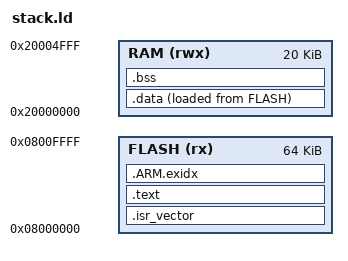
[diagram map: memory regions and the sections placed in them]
/* SPDX-License-Identifier: Apache-2.0 */
/* Copyright 2026 Junior Deogracias */
/* STM32F103C8 as common/stm32f103c8.ld, with a 2 KiB stack (__stack_limit) */
MEMORY
{
    FLASH (rx) : ORIGIN = 0x08000000, LENGTH = 64K
    RAM (rwx)  : ORIGIN = 0x20000000, LENGTH = 20K
}
ENTRY(Reset_Handler)
_estack = ORIGIN(RAM) + LENGTH(RAM);
__stack_limit = _estack - 2048;
SECTIONS
{
    .isr_vector : { KEEP(*(.isr_vector)) } > FLASH
    .text : { *(.text*) *(.rodata*) . = ALIGN(4); } > FLASH
    .ARM.exidx : { *(.ARM.exidx*) } > FLASH
    _sidata = LOADADDR(.data);
    .data : { _sdata = .; *(.data*) . = ALIGN(4); _edata = .; } > RAM AT > FLASH
    .bss (NOLOAD) : { _sbss = .; *(.bss*) *(COMMON) . = ALIGN(4); _ebss = .; } > RAM
}
